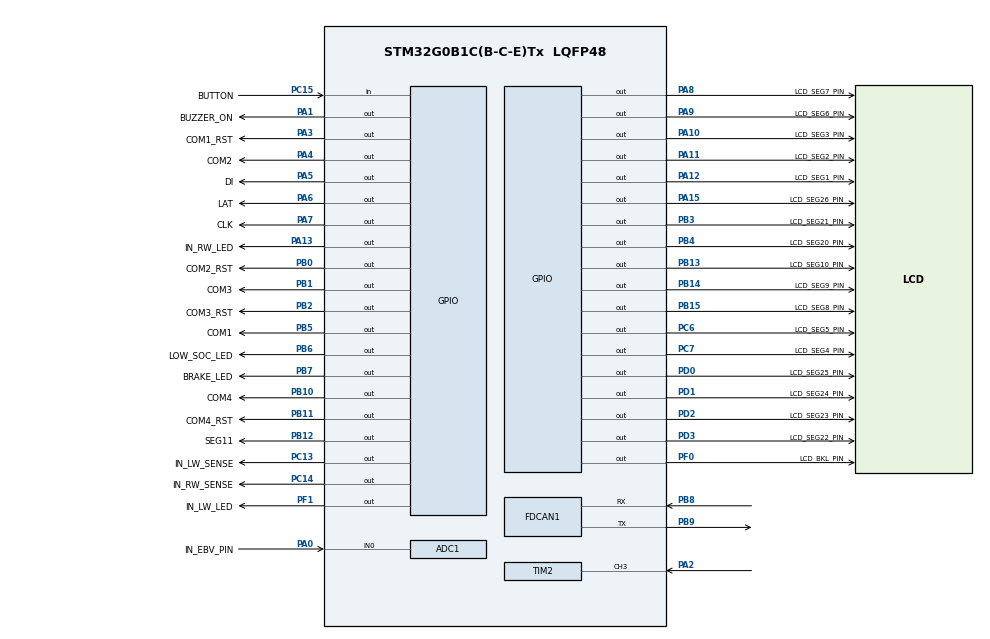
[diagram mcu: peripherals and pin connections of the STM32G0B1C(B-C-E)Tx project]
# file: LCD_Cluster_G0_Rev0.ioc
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ADC1.Channel-0\#ChannelRegularConversion=ADC_CHANNEL_0
ADC1.ClockPrescaler=ADC_CLOCK_SYNC_PCLK_DIV4
ADC1.NbrOfConversionFlag=1
ADC1.Rank-0\#ChannelRegularConversion=1
ADC1.SamplingTime-0\#ChannelRegularConversion=ADC_SAMPLINGTIME_COMMON_1
ADC1.SamplingTimeCommon1=ADC_SAMPLETIME_79CYCLES_5
ADC1.SelectedChannel=ADC_CHANNEL_0
ADC1.master=1
FDCAN1.CalculateBaudRateNominal=1333333
FDCAN1.CalculateTimeBitNominal=750
FDCAN1.CalculateTimeQuantumNominal=250.0
Mcu.Family=STM32G0
Mcu.Name=STM32G0B1C(B-C-E)Tx
Mcu.Package=LQFP48
NVIC.TIM16_FDCAN_IT0_IRQn=true\:0\:0\:false\:false\:true\:true\:true\:true
NVIC.TIM2_IRQn=true\:0\:0\:false\:false\:true\:true\:true\:true
PA0.GPIO_Label=IN_EBV_PIN
PA0.Mode=IN0
PA0.Signal=ADC1_IN0
PA1.GPIO_Label=BUZZER_ON
PA1.Signal=GPIO_Output
PA10.GPIO_Label=LCD_SEG3_PIN
PA10.GPIO_ModeDefaultOutputPP=GPIO_MODE_OUTPUT_OD
PA10.GPIO_PuPd=GPIO_NOPULL
PA10.Signal=GPIO_Output
PA11\ [PA9].GPIO_Label=LCD_SEG2_PIN
PA11\ [PA9].GPIO_ModeDefaultOutputPP=GPIO_MODE_OUTPUT_OD
PA11\ [PA9].GPIO_PuPd=GPIO_NOPULL
PA11\ [PA9].Signal=GPIO_Output
PA12\ [PA10].GPIO_Label=LCD_SEG1_PIN
PA12\ [PA10].GPIO_ModeDefaultOutputPP=GPIO_MODE_OUTPUT_OD
PA12\ [PA10].GPIO_PuPd=GPIO_NOPULL
PA12\ [PA10].Signal=GPIO_Output
PA13.GPIO_Label=IN_RW_LED
PA13.Signal=GPIO_Output
PA15.GPIO_Label=LCD_SEG26_PIN
PA15.GPIO_ModeDefaultOutputPP=GPIO_MODE_OUTPUT_OD
PA15.GPIO_PuPd=GPIO_NOPULL
PA15.Signal=GPIO_Output
PA2.Signal=S_TIM2_CH3
PA3.GPIO_Label=COM1_RST
PA3.GPIO_ModeDefaultOutputPP=GPIO_MODE_OUTPUT_OD
PA3.GPIO_PuPd=GPIO_NOPULL
PA3.Signal=GPIO_Output
PA4.GPIO_Label=COM2
PA4.GPIO_ModeDefaultOutputPP=GPIO_MODE_OUTPUT_OD
PA4.GPIO_PuPd=GPIO_NOPULL
PA4.Signal=GPIO_Output
PA5.GPIO_Label=DI
PA5.GPIO_ModeDefaultOutputPP=GPIO_MODE_OUTPUT_OD
PA5.GPIO_PuPd=GPIO_NOPULL
PA5.Signal=GPIO_Output
PA6.GPIO_Label=LAT
PA6.GPIO_ModeDefaultOutputPP=GPIO_MODE_OUTPUT_OD
PA6.GPIO_PuPd=GPIO_NOPULL
PA6.Signal=GPIO_Output
PA7.GPIO_Label=CLK
PA7.GPIO_ModeDefaultOutputPP=GPIO_MODE_OUTPUT_OD
PA7.GPIO_PuPd=GPIO_NOPULL
PA7.Signal=GPIO_Output
PA8.GPIO_Label=LCD_SEG7_PIN
PA8.GPIO_ModeDefaultOutputPP=GPIO_MODE_OUTPUT_OD
PA8.GPIO_PuPd=GPIO_NOPULL
PA8.Signal=GPIO_Output
PA9.GPIO_Label=LCD_SEG6_PIN
PA9.GPIO_ModeDefaultOutputPP=GPIO_MODE_OUTPUT_OD
PA9.GPIO_PuPd=GPIO_NOPULL
PA9.Signal=GPIO_Output
PB0.GPIO_Label=COM2_RST
PB0.GPIO_ModeDefaultOutputPP=GPIO_MODE_OUTPUT_OD
PB0.GPIO_PuPd=GPIO_NOPULL
PB0.Signal=GPIO_Output
PB1.GPIO_Label=COM3
PB1.GPIO_ModeDefaultOutputPP=GPIO_MODE_OUTPUT_OD
PB1.GPIO_PuPd=GPIO_NOPULL
PB1.Signal=GPIO_Output
PB10.GPIO_Label=COM4
PB10.GPIO_ModeDefaultOutputPP=GPIO_MODE_OUTPUT_OD
PB10.GPIO_PuPd=GPIO_NOPULL
PB10.Signal=GPIO_Output
PB11.GPIO_Label=COM4_RST
PB11.GPIO_ModeDefaultOutputPP=GPIO_MODE_OUTPUT_OD
PB11.GPIO_PuPd=GPIO_NOPULL
PB11.Signal=GPIO_Output
PB12.GPIO_Label=SEG11
PB12.Signal=GPIO_Output
PB13.GPIO_Label=LCD_SEG10_PIN
PB13.GPIO_ModeDefaultOutputPP=GPIO_MODE_OUTPUT_OD
PB13.GPIO_PuPd=GPIO_NOPULL
PB13.Signal=GPIO_Output
PB14.GPIO_Label=LCD_SEG9_PIN
PB14.GPIO_ModeDefaultOutputPP=GPIO_MODE_OUTPUT_OD
PB14.GPIO_PuPd=GPIO_NOPULL
PB14.Signal=GPIO_Output
PB15.GPIO_Label=LCD_SEG8_PIN
PB15.GPIO_ModeDefaultOutputPP=GPIO_MODE_OUTPUT_OD
PB15.GPIO_PuPd=GPIO_NOPULL
PB15.Signal=GPIO_Output
PB2.GPIO_Label=COM3_RST
PB2.GPIO_ModeDefaultOutputPP=GPIO_MODE_OUTPUT_OD
PB2.GPIO_PuPd=GPIO_NOPULL
PB2.Signal=GPIO_Output
PB3.GPIO_Label=LCD_SEG21_PIN
PB3.GPIO_ModeDefaultOutputPP=GPIO_MODE_OUTPUT_OD
PB3.GPIO_PuPd=GPIO_NOPULL
PB3.Signal=GPIO_Output
PB4.GPIO_Label=LCD_SEG20_PIN
PB4.GPIO_ModeDefaultOutputPP=GPIO_MODE_OUTPUT_OD
PB4.GPIO_PuPd=GPIO_NOPULL
PB4.Signal=GPIO_Output
PB5.GPIO_Label=COM1
PB5.GPIO_ModeDefaultOutputPP=GPIO_MODE_OUTPUT_OD
PB5.GPIO_PuPd=GPIO_NOPULL
PB5.Signal=GPIO_Output
PB6.GPIO_Label=LOW_SOC_LED
PB6.GPIO_ModeDefaultOutputPP=GPIO_MODE_OUTPUT_OD
PB6.GPIO_PuPd=GPIO_NOPULL
PB6.Signal=GPIO_Output
PB7.GPIO_Label=BRAKE_LED
PB7.GPIO_ModeDefaultOutputPP=GPIO_MODE_OUTPUT_OD
PB7.GPIO_PuPd=GPIO_NOPULL
PB7.Signal=GPIO_Output
PB8.Mode=FDCAN_Activate
PB8.Signal=FDCAN1_RX
PB9.Mode=FDCAN_Activate
PB9.Signal=FDCAN1_TX
PC13.GPIO_Label=IN_LW_SENSE
PC13.Signal=GPIO_Output
PC14-OSC32_IN\ (PC14).GPIO_Label=IN_RW_SENSE
PC14-OSC32_IN\ (PC14).Signal=GPIO_Output
PC15-OSC32_OUT\ (PC15).GPIO_Label=BUTTON
PC15-OSC32_OUT\ (PC15).Signal=GPIO_Input
PC6.GPIO_Label=LCD_SEG5_PIN
PC6.GPIO_ModeDefaultOutputPP=GPIO_MODE_OUTPUT_OD
PC6.GPIO_PuPd=GPIO_NOPULL
PC6.Signal=GPIO_Output
PC7.GPIO_Label=LCD_SEG4_PIN
PC7.GPIO_ModeDefaultOutputPP=GPIO_MODE_OUTPUT_OD
PC7.GPIO_PuPd=GPIO_NOPULL
PC7.Signal=GPIO_Output
PD0.GPIO_Label=LCD_SEG25_PIN
PD0.GPIO_ModeDefaultOutputPP=GPIO_MODE_OUTPUT_OD
PD0.GPIO_PuPd=GPIO_NOPULL
PD0.Signal=GPIO_Output
PD1.GPIO_Label=LCD_SEG24_PIN
PD1.GPIO_ModeDefaultOutputPP=GPIO_MODE_OUTPUT_OD
PD1.GPIO_PuPd=GPIO_NOPULL
PD1.Signal=GPIO_Output
PD2.GPIO_Label=LCD_SEG23_PIN
PD2.GPIO_ModeDefaultOutputPP=GPIO_MODE_OUTPUT_OD
PD2.GPIO_PuPd=GPIO_NOPULL
PD2.Signal=GPIO_Output
PD3.GPIO_Label=LCD_SEG22_PIN
PD3.GPIO_ModeDefaultOutputPP=GPIO_MODE_OUTPUT_OD
PD3.GPIO_PuPd=GPIO_NOPULL
PD3.Signal=GPIO_Output
PF0-OSC_IN\ (PF0).GPIO_Label=LCD_BKL_PIN
PF0-OSC_IN\ (PF0).Signal=GPIO_Output
PF1-OSC_OUT\ (PF1).GPIO_Label=IN_LW_LED
PF1-OSC_OUT\ (PF1).Signal=GPIO_Output
ProjectManager.HeapSize=0x200
ProjectManager.StackSize=0x400
ProjectManager.TargetToolchain=EWARM V8.50
RCC.ADCFreq_Value=64000000
RCC.AHBFreq_Value=64000000
RCC.CortexFreq_Value=64000000
RCC.EXTERNAL_CLOCK_VALUE=48000
RCC.HCLKFreq_Value=64000000
RCC.HSE_VALUE=8000000
RCC.HSI48_VALUE=48000000
RCC.HSI_VALUE=16000000
RCC.LSE_VALUE=32768
RCC.SYSCLKFreq_VALUE=64000000
RCC.SYSCLKSource=RCC_SYSCLKSOURCE_PLLCLK
RCC.USBFreq_Value=48000000
RCC.VCOOutputFreq_Value=128000000
SH.S_TIM2_CH3.0=TIM2_CH3,Input_Capture3_from_TI3
TIM2.Channel-Input_Capture3_from_TI3=TIM_CHANNEL_3
TIM2.ICPolarity_CH3=TIM_INPUTCHANNELPOLARITY_BOTHEDGE
TIM2.Period=0xFFFFF
TIM2.Prescaler=63
VP_SYS_VS_DBSignals.Mode=DisableDeadBatterySignals
board=custom

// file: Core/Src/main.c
/* USER CODE BEGIN Header */
/**
  ******************************************************************************
  * @file           : main.c
  * @brief          : Main program body
  ******************************************************************************
  * @attention
  *
  * Copyright (c) 2025 STMicroelectronics.
  * All rights reserved.
  *
  * This software is licensed under terms that can be found in the LICENSE file
  * in the root directory of this software component.
  * If no LICENSE file comes with this software, it is provided AS-IS.
  *
  ******************************************************************************
  */
/* USER CODE END Header */
#include "main.h"
#include "adc.h"
//#include "fdcan.h"
#include "iwdg.h"
#include "tim.h"

/* USER CODE BEGIN PD */
void MH595_TEST(void);
/* USER CODE END PD */

void SystemClock_Config(void);

 int main(void)
{

  /* MCU Configuration--------------------------------------------------------*/

  /* Reset of all peripherals, Initializes the Flash interface and the Systick. */
  HAL_Init();

  /* Configure the system clock */
  SystemClock_Config();

  /* Initialize all configured peripherals */
  MX_GPIO_Init();
  MX_ADC1_Init();
  MX_FDCAN1_Init();
  FDCAN_Config();
  MX_TIM2_Init();
//  MX_IWDG_Init();
  App_Init();
  /* Infinite loop */
  while (1)
  {

    /* Read Battery Voltage */
    LOW_Voltage_Detection();
    //Flag_BatteryLow = RESET; // TESTING PURPOSE

    /* Check Low battery */
    if(Flag_BatteryLow)                                                         // FLAG WILL BE SET,BATTERY VOLTAGE < 60 volt
    {
      /* Check Odo is Change or Not */
      if(Vehicle.ODO != Old_ODO) Write_OdoMeter();

      /* inifinte Loop So Odo Meter data wont be corrupted*/
      mSec_Delay(5000);
      Flag_BatteryLow = RESET;
      //while(1){__NOP();}
    }
    else
    {
      /* Odometer Reset */
//      if(LL_GPIO_IsInputPinSet(ODO_RST_PORT,ODO_RST_PIN)==RESET && Init_Time == 2){Init_Time = 0;Vehicle.ODO = 0;Write_OdoMeter();CONFIG_BUZZ();}
//      else
        if (Init_Time == 1){CONFIG_BUZZ();}

      /* extract Gear */
      Gear();

      /*Speed Calculation*/
      Cal_speed();

      /* Every Second activity */
      if(Flag_Second){GP_Timer();}

      /* managing CAN,indication,Mode,1-wire */
      Management_Process();

      /* Display Driver*/
    if(Flag_Display_Update){Flag_Display_Update = RESET; LCD_Drive();}
    }
  }
}

void Error_Handler(void)
{
  __disable_irq();
  while (1)
  {
  }
}
